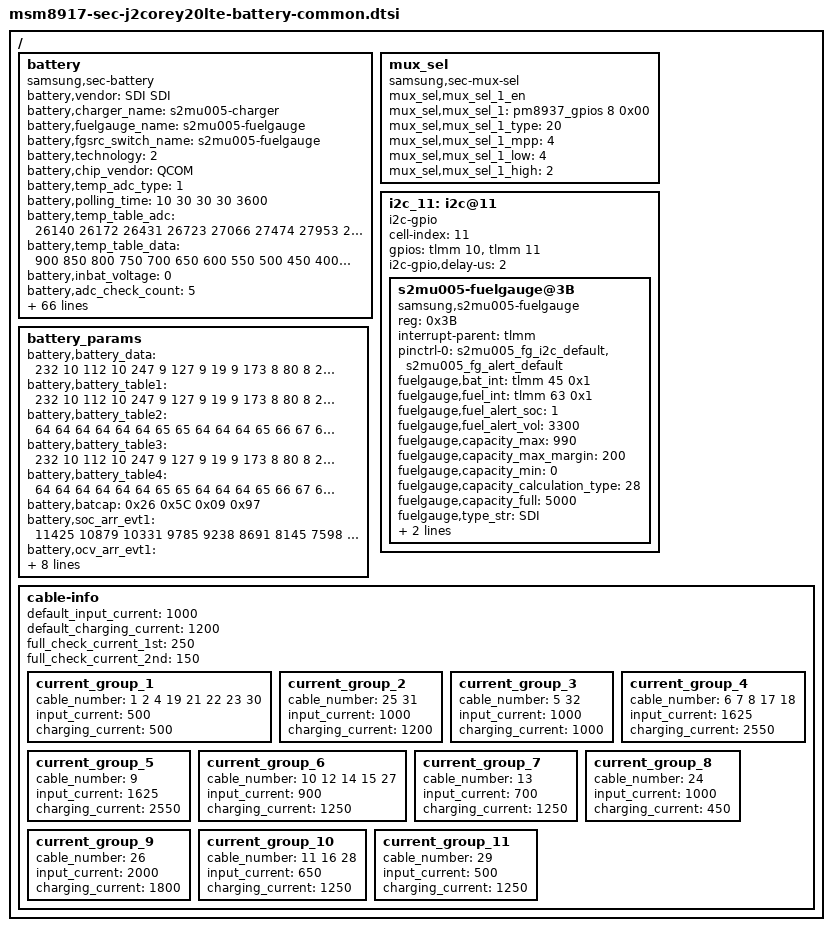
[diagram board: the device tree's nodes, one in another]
/* Copyright (c) 2015, The Linux Foundation. All rights reserved.
 *
 * This program is free software; you can redistribute it and/or modify
 * it under the terms of the GNU General Public License version 2 and
 * only version 2 as published by the Free Software Foundation.
 *
 * This program is distributed in the hope that it will be useful,
 * but WITHOUT ANY WARRANTY; without even the implied warranty of
 * MERCHANTABILITY or FITNESS FOR A PARTICULAR PURPOSE.  See the
 * GNU General Public License for more details.
 */

/ {
	battery {
		status = "okay";
		compatible = "samsung,sec-battery";
		battery,vendor = "SDI SDI";
		battery,charger_name = "s2mu005-charger";
		battery,fuelgauge_name = "s2mu005-fuelgauge";
		battery,fgsrc_switch_name = "s2mu005-fuelgauge"; /* Fuelgauge voltage source */
		battery,technology = <2>; /* POWER_SUPPLY_TECHNOLOGY_LION */
		battery,chip_vendor = "QCOM";
		
		battery,temp_adc_type = <1>; /* SEC_BATTERY_ADC_TYPE_AP */

		battery,polling_time = <10 30 30 30 3600>;

		battery,temp_table_adc = <26140 26172 26431 26723 27066 27474 27953 28492 29136 29862 30583 31973 32751 33835 34847 35867 36897 37876 38713 39527 40193 40751 41156>;
		battery,temp_table_data = <900 850 800 750 700 650 600 550 500 450 400 350 300 250 200 150 100 50 0 (-50) (-100) (-150) (-200)>;

		battery,inbat_voltage = <0>;

		battery,adc_check_count = <5>;

		battery,cable_check_type = <4>; /* SEC_BATTERY_CABLE_CHECK_PSY */
		battery,cable_source_type = <1>; /* SEC_BATTERY_CABLE_SOURCE_EXTERNAL */
		battery,polling_type = <1>; /* SEC_BATTERY_MONITOR_ALARM */
		battery,monitor_initial_count = <0>;

		battery,battery_check_type = <5>; /* SEC_BATTERY_CHECK_CHARGER */
		battery,check_count = <0>;

		battery,check_adc_max = <1440>;
		battery,check_adc_min = <0>;

		battery,ovp_uvlo_check_type = <3>; /* SEC_BATTERY_OVP_UVLO_CHGPOLLING */

		battery,thermal_source = <2>; /* SEC_BATTERY_THERMAL_SOURCE_ADC */
		battery,chg_thermal_source = <0>;
		battery,chg_temp_check = <0>;

		battery,adc_channels = <0x13>;
		battery,channel_names = "adc-temp";
		battery,channel_cells = <1>;

		battery,temp_check_type = <2>; /* SEC_BATTERY_TEMP_CHECK_TEMP */
		battery,temp_check_count = <1>;
		battery,temp_highlimit_threshold_normal = <800>;
		battery,temp_highlimit_recovery_normal = <750>;
		battery,temp_high_threshold_normal = <500>;
		battery,temp_high_recovery_normal = <480>;
		battery,temp_low_threshold_normal = <0>;
		battery,temp_low_recovery_normal = <20>;
		battery,temp_highlimit_threshold_lpm = <800>;
		battery,temp_highlimit_recovery_lpm = <750>;
		battery,temp_high_threshold_lpm = <500>;
		battery,temp_high_recovery_lpm = <480>;
		battery,temp_low_threshold_lpm = <0>;
		battery,temp_low_recovery_lpm = <20>;

		battery,full_check_type = <2>; /* SEC_BATTERY_FULLCHARGED_FG_CURRENT */
		battery,full_check_type_2nd = <2>; /* SEC_BATTERY_FULLCHARGED_FG_CURRENT */
		battery,full_check_count = <1>;
		battery,chg_gpio_full_check = <0>;
		battery,chg_polarity_full_check = <1>;

		/* SEC_BATTERY_FULL_CONDITION_SOC |
		   SEC_BATTERY_FULL_CONDITION_NOTIMEFULL |
		   SEC_BATTERY_FULL_CONDITION_VCELL */
		battery,full_condition_type = <13>;
		battery,full_condition_soc = <93>;
		battery,full_condition_vcell = <4290>;

		battery,recharge_check_count = <2>;
		battery,recharge_condition_type = <4>; /* SEC_BATTERY_RECHARGE_CONDITION_VCELL */
		battery,recharge_condition_soc = <98>;
		battery,recharge_condition_vcell = <4200>;

		battery,expired_time = <16800>;      /* 200min + 80min margin */
		battery,recharging_expired_time = <5400>;
		battery,standard_curr = <1045>; /* IP < CP */

		battery,swelling_high_temp_block = <410>;
		battery,swelling_high_temp_recov = <390>;

		battery,swelling_low_temp_2step_mode = <1>;
		battery,swelling_low_temp_block_1st = <150>;
		battery,swelling_low_temp_recov_1st = <170>;
		battery,swelling_low_temp_block_2nd = <50>;
		battery,swelling_low_temp_recov_2nd = <70>;

		battery,swelling_low_temp_current = <750>;	/* 0.3C */
		battery,swelling_low_temp_topoff = <130>;	/* 0.05C */
		battery,swelling_high_temp_current = <1100>;	/* 0.45C */
		battery,swelling_high_temp_topoff = <130>;	/* 0.05C */

		battery,swelling_drop_float_voltage = <4100>;
		battery,swelling_high_rechg_voltage = <3950>;
		battery,swelling_low_rechg_voltage = <3950>;

		battery,siop_input_limit_current = <1000>;
		battery,siop_charging_limit_current = <1000>;

		battery,chg_float_voltage = <4300>;
		battery,mivr_voltage = <1>; /* 0:  4200, 1 : 4300, 2 : 4400 ..... 7: 4900 */

		battery,cisd_max_voltage_thr = <5000>;

		/* cycle(week), chg_float_voltage, recharge_condition_vcell, full_condition_vcell, full_condition_soc*/
		battery,age_data = <0 4300 4200 4200 93
				28 4280 4180 4180 91
				36 4260 4160 4160 89>;

		qcom,sec-battery-vadc = <&pm8937_vadc>;
	};


	mux_sel {
		compatible = "samsung,sec-mux-sel";
		mux_sel,mux_sel_1_en;
		mux_sel,mux_sel_1 = <&pm8937_gpios 8 0x00>;
		mux_sel,mux_sel_1_type = <20>; /* BATT_THM_MUX_SEL | AP_THM_MUX_SEL */
		mux_sel,mux_sel_1_mpp = <4>; /* SEC_MPP4_MUX_SEL */
		mux_sel,mux_sel_1_low = <4>; /* SEC_MUX_SEL_AP_THM */
		mux_sel,mux_sel_1_high = <2>; /* SEC_MUX_SEL_BATT_THM */
	};

	i2c_11: i2c@11 {
		cell-index = <11>;
		compatible = "i2c-gpio";
		gpios = <&tlmm 10 0	/* sda */
			&tlmm 11 0	/* scl */
			>;
		i2c-gpio,delay-us = <2>;
		#address-cells = <1>;
		#size-cells = <0>;

		s2mu005-fuelgauge@3B{
			status = "okay";
			compatible = "samsung,s2mu005-fuelgauge";
			reg = <0x3B>;
			interrupt-parent = <&tlmm>;
			pinctrl-names = "default";
			pinctrl-0 = <&s2mu005_fg_i2c_default &s2mu005_fg_alert_default>;
			fuelgauge,bat_int = <&tlmm 45 0x1>;
			fuelgauge,fuel_int = <&tlmm 63 0x1>;
			fuelgauge,fuel_alert_soc = <1>;
			fuelgauge,fuel_alert_vol = <3300>;
			fuelgauge,capacity_max = <990>;
			fuelgauge,capacity_max_margin = <200>;
			fuelgauge,capacity_min = <0>;
			fuelgauge,capacity_calculation_type = <28>;
			fuelgauge,capacity_full = <5000>; /* battery capacity */
			fuelgauge,type_str = "SDI";
			fuelgauge,model_type = <1>;
			fuelgauge,fg_log_enable = <1>;
		};
	};
	
	battery_params {
		battery,battery_data =
			<
			/***** battery data for 4.30 *****/
			/* battery,battery_table3 */
			232 10 112 10 247 9 127 9 19 9
			173 8 80 8 224 7 166 7 89 7 
			244 6 179 6 137 6 103 6 77 6 
			56 6 31 6 246 5 196 5 143 5 
			36 5 43 3 215 8 106 8 254 7 
			146 7 38 7 185 6 77 6 225 5 
			116 5 8 5 156 4 48 4 195 3 
			87 3 235 2 127 2 18 2 166 1
			58 1 205 0 97 0 245 15
			
			/* battery,battery_table4 */
			10 10 10 10 64 64 65 65 64 64
			64 65 66 67 68 70 71 75 81 98
			136 128
			
			/* battery,batcap */
			0x27 0x9C 0x05 0xF1 /* [0x0F] [0x0E] [0x11] [0x10] */
			
			/* battery,accum */ 
			0x00 0x08 /* [0x44] [0x45] */
			
			/* battery,soc_arr_val */
			11049 10520 9991 9463 8934 8405 7876 7348 6818 6290
			5760 5233 4704 4175 3646 3118 2589 2060 1531 1003
			474 (-55)
			
			/* battery,ocv_arr_val */
			43632 43045 42458 41872 41345 40847 40391 39844 39559 39184
			38691 38376 38167 38003 37877 37773 37650 37449 37205 36949
			36424 33960
			
			/* battery,volt_mode_tunning */
			0x00 /* [0x13] */

			/***** battery data for 4.28 *****/
			/* battery,battery_table3 */
			232 10 112 10 247 9 127 9 19 9
			173 8 80 8 224 7 166 7 89 7
			244 6 179 6 137 6 103 6 77 6
			56 6 31 6 246 5 196 5 143 5
			36 5 43 3 5 9 151 8 41 8
			187 7 77 7 222 6 112 6 2 6
			148 5 37 5 183 4 73 4 219 3
			109 3 254 2 144 2 34 2 180 1
			69 1 215 0 105 0 251 15

			/* battery,battery_table4 */
			64 64 64 64 64 64 65 65 64 64
			64 65 66 67 68 70 71 75 81 98
			136 128

			/* battery,batcap */
			0x25 0x80 0x09 0x60 /* [0x0F] [0x0E] [0x11] [0x10] */
			
			/* battery,accum */
			0x00 0x8 /* [0x44] [0x45] */

			/* battery,soc_arr_val */
			11277 10739 10201 9663 9124 8586 8048 7509 6971 6433
			5895 5356 4818 4280 3741 3202 2665 2127 1588 1050
			512 (-26)
			
			/* battery,ocv_arr_val */
			43632 43045 42458 41872 41345 40847 40391 39844 39559 39184
			38691 38376 38167 38003 37877 37773 37650 37449 37205 36949
			36424 33960
			
			/* battery,volt_mode_tunning */
			0x00 /* [0x13] */

			/***** battery data for 4.26 *****/
			/* battery,battery_table3 */
			232 10 112 10 247 9 127 9 19 9
			173 8 80 8 224 7 166 7 89 7
			244 6 179 6 137 6 103 6 77 6
			56 6 31 6 246 5 196 5 143 5
			36 5 43 3 40 9 184 8 72 8
			216 7 104 7 249 6 137 6 25 6
			169 5 57 5 201 4 89 4 233 3
			121 3 10 3 154 2 42 2 186 1
			74 1 218 0 106 0 251 15

			/* battery,battery_table4 */
			64 64 64 64 64 64 65 65 64 64
			64 65 66 67 68 70 71 75 81 98
			136 128

			/* battery,batcap */
			0x24 0xB8 0x09 0x2E /* [0x0F] [0x0E] [0x11] [0x10] */ 
			
			/* battery,accum */
			0x00 0x8 /* [0x44] [0x45] */

			/* battery,soc_arr_val */
			11445 10899 10353 9806 9260 8714 8168 7621 7075 6529
			5981 5436 4890 4343 3797 3251 2705 2158 1612 1066
			519 (-27)

			/* battery,ocv_arr_val */
			43632 43045 42458 41872 41345 40847 40391 39844 39559 39184
			38691 38376 38167 38003 37877 37773 37650 37449 37205 36949
			36424 33960
			
			/* battery,volt_mode_tunning */
			0x00 /* [0x13] */

			/***** battery data for 4.24 *****/
			/* battery,battery_table3 */
			232 10 112 10 247 9 127 9 19 9
			173 8 80 8 224 7 166 7 89 7
			244 6 179 6 137 6 103 6 77 6
			56 6 31 6 246 5 196 5 143 5
			36 5 43 3 91 9 233 8 118 8
			4 8 146 7 31 7 173 6 59 6
			200 5 86 5 228 4 113 4 255 3
			141 3 27 3 168 2 54 2 196 1
			81 1 223 0 109 0 251 15

			/* battery,battery_table4 */
			64 64 64 64 64 64 65 65 64 64
			64 65 66 67 68 70 71 75 81 98
			136 128

			/* battery,batcap */
			0x23 0xF0 0x08 0xFC /* [0x0F] [0x0E] [0x11] [0x10] */
			
			/* battery,accum */
			0x00 0x8 /* [0x44] [0x45] */

			/* battery,soc_arr_val */
			11694 11136 10578 10020 9461 8903 8345 7786 7229 6671
			6112 5554 4996 4438 3880 3322 2763 2205 1647 1089
			531 (-27)
			
			/* battery,ocv_arr_val */
			43632 43045 42458 41872 41345 40847 40391 39844 39559 39184
			38691 38376 38167 38003 37877 37773 37650 37449 37205 36949
			36424 33960
			
			/* battery,volt_mode_tunning */
			0x00 /* [0x13] */

			/***** battery data for 4.19 *****/
			/* battery,battery_table3 */
			232 10 112 10 247 9 127 9 19 9
			173 8 80 8 224 7 166 7 89 7
			244 6 179 6 137 6 103 6 77 6
			56 6 31 6 246 5 196 5 143 5
			36 5 43 3 223 9 102 9 238 8
			117 8 252 7 132 7 11 7 147 6
			26 6 161 5 41 5 176 4 55 4
			191 3 70 3 206 2 85 2 221 1
			100 1 235 0 115 0 250 15

			/* battery,battery_table4 */
			64 64 64 64 64 64 65 65 64 64
			64 65 66 67 68 70 71 75 81 98
			136 128

			/* battery,batcap */
			0x22 0x60 0x08 0x98 /* [0x0F] [0x0E] [0x11] [0x10] */
			
			/* battery,accum */
			0x00 0x8 /* [0x44] [0x45] */

			/* battery,soc_arr_val */
			12338 11749 11160 10571 9982 9393 8804 8216 7627 7038
			6449 5860 5271 4682 4093 3504 2916 2327 1738 1149
			560 (-28)
			
			/* battery,ocv_arr_val */
			43632 43045 42458 41872 41345 40847 40391 39844 39559 39184
			38691 38376 38167 38003 37877 37773 37650 37449 37205 36949
			36424 33960
			
			/* battery,volt_mode_tunning */
			0x00 /* [0x13] */
			
			>;
			
			battery,battery_table1 = <
					232 10 112 10 247 9 127 9 19 9
					173 8 80 8 224 7 166 7 89 7
					244 6 179 6 137 6 103 6 77 6
					56 6 31 6 246 5 196 5 143 5
					36 5 43 3 36 9 180 8 68 8
					212 7 100 7 244 6 132 6 20 6
					164 5 52 5 196 4 84 4 228 3
					116 3 4 3 148 2 36 2 180 1
					68 1 212 0 100 0 244 15
					>;

			battery,battery_table2 = <
					64 64 64 64 64 64 65 65 64 64
					64 65 66 67 68 70 71 75 81 98
					90 90
					>;

			battery,battery_table3 = <
					232 10 112 10 247 9 127 9 19 9
					173 8 80 8 224 7 166 7 89 7
					244 6 179 6 137 6 103 6 77 6
					56 6 31 6 246 5 196 5 143 5
					36 5 43 3 36 9 180 8 68 8
					212 7 100 7 244 6 132 6 20 6
					164 5 52 5 196 4 84 4 228 3
					116 3 4 3 148 2 36 2 180 1
					68 1 212 0 100 0 244 15
					>;

			battery,battery_table4 = <
					64 64 64 64 64 64 65 65 64 64
					64 65 66 67 68 70 71 75 81 98
					90 90
					>;

			battery,batcap = <0x26 0x5C 0x09 0x97>; /* [0x0F] [0x0E] [0x11] [0x10] */

			battery,soc_arr_evt1 = <
						11425 10879 10331 9785 9238 8691 8145 7598 7050 6504
						5958 5411 4864 4317 3771 3224 2677 2130 1584 1037
						490 (-57)
						>;
			battery,ocv_arr_evt1 = <
						43632 43045 42458 41872 41345 40847 40391 39844 39559 39184
						38691 38376 38167 38003 37877 37773 37650 37449 37205 36949
						36424 33960
						>;

			battery,soc_arr_evt2 = <
						11425 10879 10331 9785 9238 8691 8145 7598 7050 6504
						5958 5411 4864 4317 3771 3224 2677 2130 1584 1037
						490 (-57)
						>;
			battery,ocv_arr_evt2 = <
						43632 43045 42458 41872 41345 40847 40391 39844 39559 39184
						38691 38376 38167 38003 37877 37773 37650 37449 37205 36949
						36424 33960
						>;

			battery,FG_Accumulative_rate_evt2 = <0x00 0x08>; /* 0x44 0x45 */
			battery,volt_mode_tunning = <0x00>; /* [0x13] */
			battery,data_ver = <0x05>;
	};
	
	/* sec_battery_cable
 *   0	UNKNOWN,
 *   1	NONE,
 *   2	PREPARE_TA,
 *   3	TA,
 *   4	USB,
 *   5	USB_CDP,
 *   6	9V_TA,
 *   7	9V_ERR,
 *   8	9V_UNKNOWN,
 *   9	12V_TA,
 *  10	WIRELESS,
 *  11	HV_WIRELESS,
 *  12	PMA_WIRELESS,
 *  13	WIRELESS_PACK,
 *  14	WIRELESS_PACK_TA,
 *  15	WIRELESS_STAND,
 *  16	WIRELESS_HV_STAND,
 *  17	QC20,
 *  18	QC30,
 *  19	PDIC,
 *  20	UARTOFF,
 *  21	OTG,
 *  22	LAN_HUB,
 *  23	POWER_SHARING,
 *  24	HMT_CONNECTED,
 *  25	HMT_CHARGE,
 *  26	HV_TA_CHG_LIMIT,
 *  27	WIRELESS_VEHICLE,
 *  28	WIRELESS_HV_VEHICLE,
 *  29	PREPARE_WIRELESS_HV,
 *  30  TIMEOUT,
 *  31  SMART_OTG,
 *  32  SMART_NOTG,
 *  33	CABLE_MAX,
 */
	cable-info {
		default_input_current = <1000>;
		default_charging_current = <1200>;
		full_check_current_1st = <250>;
		full_check_current_2nd = <150>;
		current_group_1 {
			cable_number = <1 2 4 19 21 22 23 30>;
			input_current = <500>;
			charging_current = <500>;
		};
		current_group_2 {
			cable_number = <25 31>;
			input_current = <1000>;
			charging_current = <1200>;
		};
		current_group_3 {
			cable_number = <5 32>;
			input_current = <1000>;
			charging_current = <1000>;
		};
		current_group_4 {
			cable_number = <6 7 8 17 18>;
			input_current = <1625>;
			charging_current = <2550>;
		};
		current_group_5 {
			cable_number = <9>;
			input_current = <1625>;
			charging_current = <2550>;
		};
		current_group_6 {
			cable_number = <10 12 14 15 27>;
			input_current = <900>;
			charging_current = <1250>;
		};
		current_group_7 {
			cable_number = <13>;
			input_current = <700>;
			charging_current = <1250>;
		};
		current_group_8 {
			cable_number = <24>;
			input_current = <1000>;
			charging_current = <450>;
		};
		current_group_9 {
			cable_number = <26>;
			input_current = <2000>;
			charging_current = <1800>;
		};
		current_group_10 {
			cable_number = <11 16 28>;
			input_current = <650>;
			charging_current = <1250>;
		};
		current_group_11 {
			cable_number = <29>;
			input_current = <500>;
			charging_current = <1250>;
		};
	};
};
